VERSION "AUTOSAR_CONFIGURATOR_TEST_1.0"

NS_ :

BS_:

BU_: Gateway PT_ECU Brake_ECU Body_ECU Cluster Tester

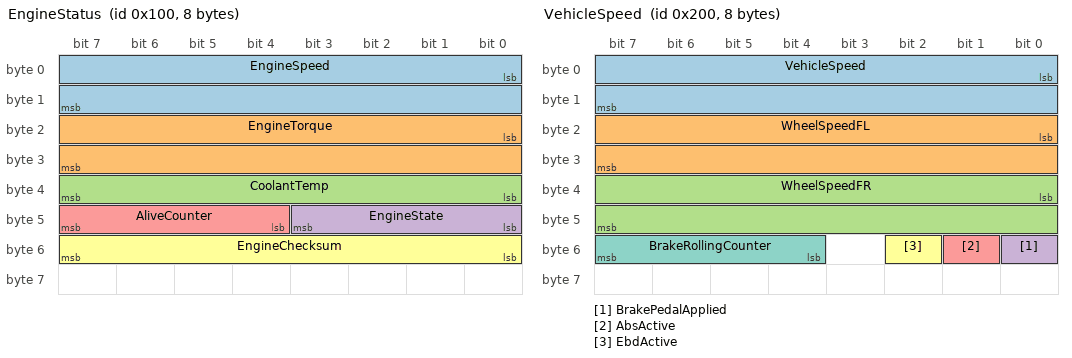
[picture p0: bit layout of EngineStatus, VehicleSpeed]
BO_ 256 EngineStatus: 8 PT_ECU
 SG_ EngineSpeed : 0|16@1+ (0.125,0) [0|8031.875] "rpm" Cluster,Gateway
 SG_ EngineTorque : 16|16@1- (0.1,-3200) [-3200|3223.5] "Nm" Gateway
 SG_ CoolantTemp : 32|8@1+ (1,-40) [-40|215] "degC" Cluster,Gateway
 SG_ EngineState : 40|4@1+ (1,0) [0|15] "" Cluster,Gateway
 SG_ AliveCounter : 44|4@1+ (1,0) [0|15] "" Gateway
 SG_ EngineChecksum : 48|8@1+ (1,0) [0|255] "" Gateway

BO_ 512 VehicleSpeed: 8 Brake_ECU
 SG_ VehicleSpeed : 0|16@1+ (0.01,0) [0|250] "km/h" Cluster,PT_ECU,Gateway
 SG_ WheelSpeedFL : 16|16@1+ (0.01,0) [0|250] "km/h" PT_ECU,Gateway
 SG_ WheelSpeedFR : 32|16@1+ (0.01,0) [0|250] "km/h" PT_ECU,Gateway
 SG_ BrakePedalApplied : 48|1@1+ (1,0) [0|1] "" PT_ECU,Gateway
 SG_ AbsActive : 49|1@1+ (1,0) [0|1] "" PT_ECU,Gateway
 SG_ EbdActive : 50|1@1+ (1,0) [0|1] "" PT_ECU,Gateway
 SG_ BrakeRollingCounter : 52|4@1+ (1,0) [0|15] "" Gateway

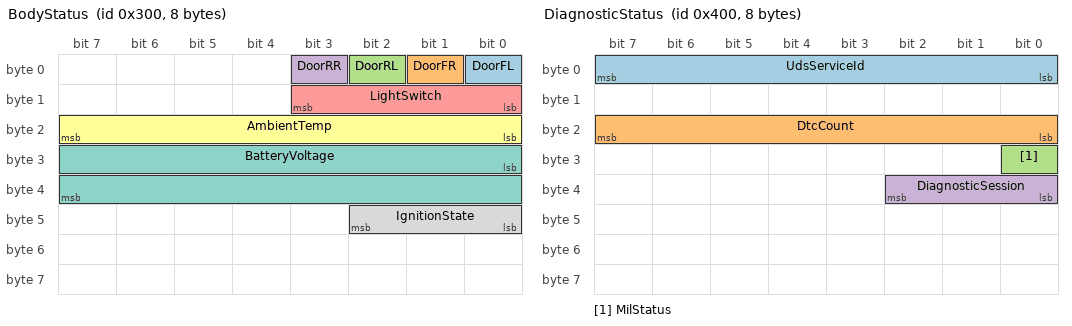
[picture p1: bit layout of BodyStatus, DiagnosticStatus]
BO_ 768 BodyStatus: 8 Body_ECU
 SG_ DoorFL : 0|1@1+ (1,0) [0|1] "" Cluster,Gateway
 SG_ DoorFR : 1|1@1+ (1,0) [0|1] "" Cluster,Gateway
 SG_ DoorRL : 2|1@1+ (1,0) [0|1] "" Cluster,Gateway
 SG_ DoorRR : 3|1@1+ (1,0) [0|1] "" Cluster,Gateway
 SG_ LightSwitch : 8|4@1+ (1,0) [0|15] "" Cluster,Gateway
 SG_ AmbientTemp : 16|8@1+ (1,-40) [-40|215] "degC" Cluster,Gateway
 SG_ BatteryVoltage : 24|16@1+ (0.001,0) [0|18] "V" Gateway
 SG_ IgnitionState : 40|3@1+ (1,0) [0|7] "" Gateway,PT_ECU

BO_ 1024 DiagnosticStatus: 8 Gateway
 SG_ UdsServiceId : 7|8@0+ (1,0) [0|255] "" Tester
 SG_ DtcCount : 16|8@1+ (1,0) [0|255] "" Tester
 SG_ MilStatus : 24|1@1+ (1,0) [0|1] "" Cluster,Tester
 SG_ DiagnosticSession : 32|3@1+ (1,0) [0|7] "" Tester

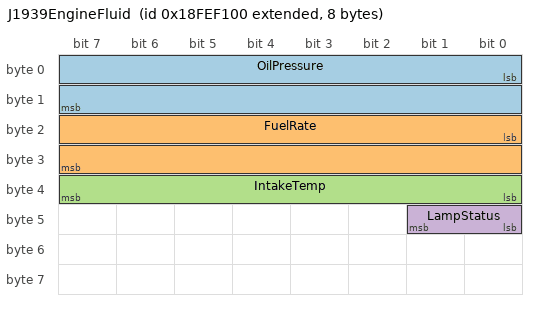
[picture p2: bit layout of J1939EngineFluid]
BO_ 2566844672 J1939EngineFluid: 8 PT_ECU
 SG_ OilPressure : 0|16@1+ (0.5,0) [0|32127.5] "kPa" Gateway,Tester
 SG_ FuelRate : 16|16@1+ (0.05,0) [0|3212.75] "L/h" Gateway
 SG_ IntakeTemp : 32|8@1+ (1,-40) [-40|215] "degC" Gateway
 SG_ LampStatus : 40|2@1+ (1,0) [0|3] "" Gateway

CM_ BO_ 256 "Powertrain engine status broadcast at 10 ms.";
CM_ BO_ 512 "Brake controller speed and ABS status broadcast at 20 ms.";
CM_ BO_ 768 "Body controller door, lighting, ignition and voltage status.";
CM_ BO_ 1024 "Gateway diagnostic status with Motorola byte order service id.";
CM_ BO_ 2566844672 "J1939-style 29-bit extended frame. Raw DBC id has bit 31 set.";

BA_DEF_ BO_ "GenMsgCycleTime" INT 0 65535;

BA_ "GenMsgCycleTime" BO_ 256 10;
BA_ "GenMsgCycleTime" BO_ 512 20;
BA_ "GenMsgCycleTime" BO_ 768 100;
BA_ "GenMsgCycleTime" BO_ 1024 1000;
BA_ "GenMsgCycleTime" BO_ 2566844672 100;

VAL_ 256 EngineState 0 "Off" 1 "Cranking" 2 "Running" 3 "Stopping" 4 "Error";
VAL_ 512 BrakePedalApplied 0 "Released" 1 "Applied";
VAL_ 512 AbsActive 0 "Inactive" 1 "Active";
VAL_ 768 IgnitionState 0 "Off" 1 "Accessory" 2 "Run" 3 "Start";
VAL_ 1024 DiagnosticSession 1 "Default" 2 "Programming" 3 "Extended";
VAL_ 2566844672 LampStatus 0 "Off" 1 "On" 2 "Error" 3 "NotAvailable";
